# STM32MP153 register map
File version: 1.3
CPU: CM4 r0p1, little endian, no MPU, FPU, 4 interrupt priority bits
Registers are 32-bit, read-write, reset 0x0 unless marked. A register's access mark holds for its fields unless they carry their own. Offsets are from the block's base; [hi:lo] are bit positions; {n}, {i} and the like mark numbered series.

## SDMMC1
Base 0x58005000
Same registers: SDMMC3 0x48004000, SDMMC2 0x58007000
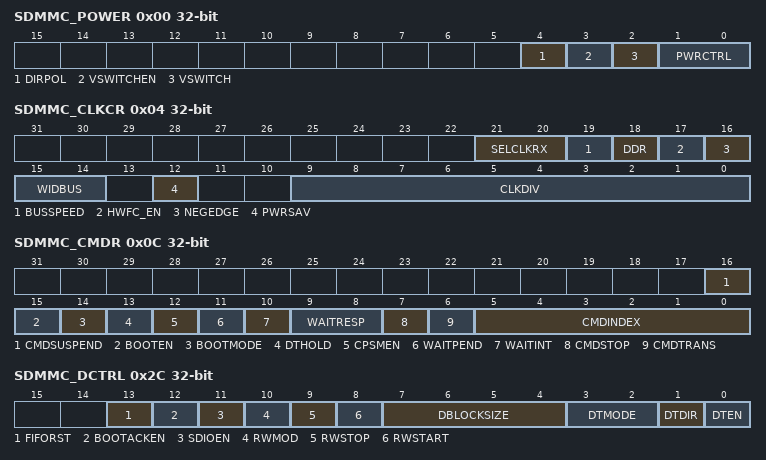
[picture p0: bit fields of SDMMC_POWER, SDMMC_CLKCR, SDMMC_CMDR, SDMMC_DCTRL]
0x00 SDMMC_POWER — SDMMC power control register
  [4] DIRPOL, [3] VSWITCHEN, [2] VSWITCH, [1:0] PWRCTRL
0x04 SDMMC_CLKCR — The SDMMC_CLKCR register controls the SDMMC_CK output clock, the sdmmc_rx_ck receive clock, and the bus width.
  [21:20] SELCLKRX, [19] BUSSPEED, [18] DDR, [17] HWFC_EN, [16] NEGEDGE, [15:14] WIDBUS, [12] PWRSAV, [9:0] CLKDIV
0x08 SDMMC_ARGR — The SDMMC_ARGR register contains a 32-bit command argument, which is sent to a card as part of a command message.
  [31:0] CMDARG
0x0C SDMMC_CMDR — The SDMMC_CMDR register contains the command index and command type bits. The command index is sent to a card as part of a command message. The command type bits control the command path state machine (CPSM).
  [16] CMDSUSPEND, [15] BOOTEN, [14] BOOTMODE, [13] DTHOLD, [12] CPSMEN, [11] WAITPEND, [10] WAITINT, [9:8] WAITRESP, [7] CMDSTOP, [6] CMDTRANS, [5:0] CMDINDEX
0x10 SDMMC_RESPCMDR ro — The SDMMC_RESPCMDR register contains the command index field of the last command response received. If the command response transmission does not contain the command index field (long or OCR response), the RESPCMD field is unknown, although it must contain 111111b (the value of the reserved field from the response).
  [5:0] RESPCMD
{0x10+4i} SDMMC_RESP{i}R ro (i=1..4) — The SDMMC_RESP1/2/3/4R registers contain the status of a card, which is part of the received response.
  [31:0] CARDSTATUS{i}
0x24 SDMMC_DTIMER — The SDMMC_DTIMER register contains the data timeout period, in card bus clock periods. A counter loads the value from the SDMMC_DTIMER register, and starts decrementing when the data path state machine (DPSM) enters the Wait_R or Busy state. If the timer reaches 0 while the DPSM is in either of these states, the timeout status flag is set.
  [31:0] DATATIME
0x28 SDMMC_DLENR — The SDMMC_DLENR register contains the number of data bytes to be transferred. The value is loaded into the data counter when data transfer starts.
  [24:0] DATALENGTH
0x2C SDMMC_DCTRL — The SDMMC_DCTRL register control the data path state machine (DPSM).
  [13] FIFORST, [12] BOOTACKEN, [11] SDIOEN, [10] RWMOD, [9] RWSTOP, [8] RWSTART, [7:4] DBLOCKSIZE, [3:2] DTMODE, [1] DTDIR, [0] DTEN
0x30 SDMMC_DCNTR ro — The SDMMC_DCNTR register loads the value from the data length register (see SDMMC_DLENR) when the DPSM moves from the Idle state to the Wait_R or Wait_S state. As data is transferred, the counter decrements the value until it reaches 0. The DPSM then moves to the Idle state and when there has been no error, the data status end flag (DATAEND) is set.
  [24:0] DATACOUNT
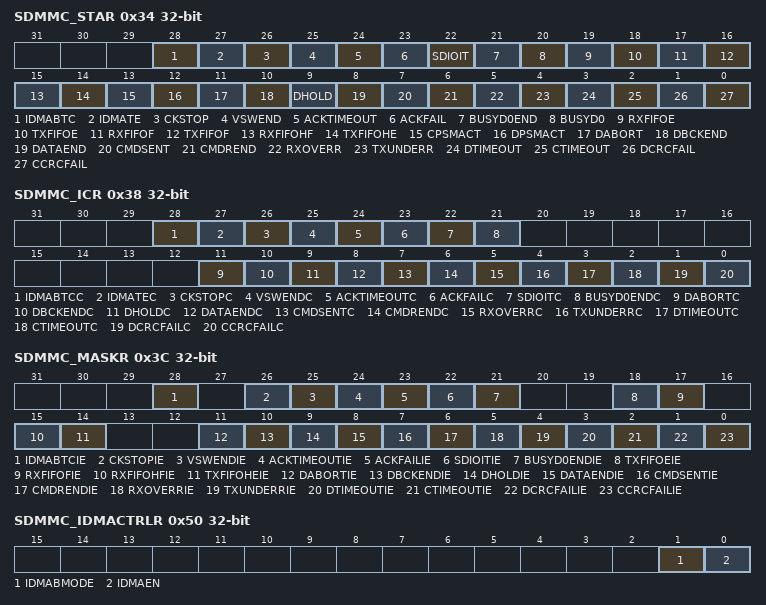
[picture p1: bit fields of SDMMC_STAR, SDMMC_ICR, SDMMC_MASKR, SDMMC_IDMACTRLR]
0x34 SDMMC_STAR ro — The SDMMC_STAR register is a read-only register. It contains two types of flag: Static flags (bits [28, 21, 11:0]): these bits remain asserted until they are cleared by writing to the SDMMC interrupt Clear register (see SDMMC_ICR) Dynamic flags (bits [20:12]): these bits change state depending on the state of the underlying logic (for example, FIFO full and empty flags are asserted and de-asserted as data while written to the FIFO)
  [28] IDMABTC, [27] IDMATE, [26] CKSTOP, [25] VSWEND, [24] ACKTIMEOUT, [23] ACKFAIL, [22] SDIOIT, [21] BUSYD0END, [20] BUSYD0, [19] RXFIFOE, [18] TXFIFOE, [17] RXFIFOF, [16] TXFIFOF, [15] RXFIFOHF, [14] TXFIFOHE, [13] CPSMACT, [12] DPSMACT, [11] DABORT, [10] DBCKEND, [9] DHOLD, [8] DATAEND, [7] CMDSENT, [6] CMDREND, [5] RXOVERR, [4] TXUNDERR, [3] DTIMEOUT, [2] CTIMEOUT, [1] DCRCFAIL, [0] CCRCFAIL
0x38 SDMMC_ICR — The SDMMC_ICR register is a write-only register. Writing a bit with 1 clears the corresponding bit in the SDMMC_STAR status register.
  [28] IDMABTCC, [27] IDMATEC, [26] CKSTOPC, [25] VSWENDC, [24] ACKTIMEOUTC, [23] ACKFAILC, [22] SDIOITC, [21] BUSYD0ENDC, [11] DABORTC, [10] DBCKENDC, [9] DHOLDC, [8] DATAENDC, [7] CMDSENTC, [6] CMDRENDC, [5] RXOVERRC, [4] TXUNDERRC, [3] DTIMEOUTC, [2] CTIMEOUTC, [1] DCRCFAILC, [0] CCRCFAILC
0x3C SDMMC_MASKR — The interrupt mask register determines which status flags generate an interrupt request by setting the corresponding bit to 1.
  [28] IDMABTCIE, [26] CKSTOPIE, [25] VSWENDIE, [24] ACKTIMEOUTIE, [23] ACKFAILIE, [22] SDIOITIE, [21] BUSYD0ENDIE, [18] TXFIFOEIE, [17] RXFIFOFIE, [15] RXFIFOHFIE, [14] TXFIFOHEIE, [11] DABORTIE, [10] DBCKENDIE, [9] DHOLDIE, [8] DATAENDIE, [7] CMDSENTIE, [6] CMDRENDIE, [5] RXOVERRIE, [4] TXUNDERRIE, [3] DTIMEOUTIE, [2] CTIMEOUTIE, [1] DCRCFAILIE, [0] CCRCFAILIE
0x40 SDMMC_ACKTIMER — The SDMMC_ACKTIMER register contains the acknowledgment timeout period, in SDMMC_CK bus clock periods. A counter loads the value from the SDMMC_ACKTIMER register, and starts decrementing when the data path state machine (DPSM) enters the Wait_Ack state. If the timer reaches 0 while the DPSM is in this states, the acknowledgment timeout status flag is set.
  [24:0] ACKTIME
0x50 SDMMC_IDMACTRLR — The receive and transmit FIFOs can be read or written as 32-bit wide registers. The FIFOs contain 32 entries on 32 sequential addresses. This allows the CPU to use its load and store multiple operands to read from/write to the FIFO.
  [1] IDMABMODE, [0] IDMAEN
0x54 SDMMC_IDMABSIZER — The SDMMC_IDMABSIZER register contains the buffer size when in linked list configuration.
  [16:5] IDMABNDT
0x58 SDMMC_IDMABASER — The SDMMC_IDMABASER register contains the memory buffer base address in single buffer configuration and linked list configuration.
  [31:0] IDMABASE
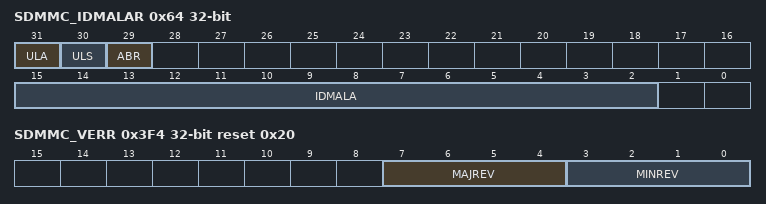
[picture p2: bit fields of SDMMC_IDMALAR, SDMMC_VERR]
0x64 SDMMC_IDMALAR — SDMMC IDMA linked list address register
  [31] ULA, [30] ULS, [29] ABR, [15:2] IDMALA
0x68 SDMMC_IDMABAR — SDMMC IDMA linked list memory base register
  [31:2] IDMABA
{0x80+4i} SDMMC_FIFOR{i} (i=0..15) — The receive and transmit FIFOs can be only read or written as word (32-bit) wide registers. The FIFOs contain 16 entries on sequential addresses. This allows the CPU to use its load and store multiple operands to read from/write to the FIFO. The FIFO register interface takes care of correct data alignment inside the FIFO, the FIFO register address used by the CPU does matter. When accessing SDMMC_FIFOR with half word or byte access an AHB bus fault is generated.
  [31:0] FIFODATA
0x3F4 SDMMC_VERR ro reset 0x20 — SDMMC version register
  [7:4] MAJREV, [3:0] MINREV
0x3F8 SDMMC_IPIDR ro reset 0x140022 — SDMMC identification register
  [31:0] IP_ID
0x3FC SDMMC_SIDR ro reset 0xA3C5DD01 — SDMMC size ID register
  [31:0] SID
